# R7FA6M1AD register map
Vendor: Renesas; Series: RA6; File version: 1.2
CPU: CM4 r0p1, little endian, MPU, FPU, VTOR, 4 interrupt priority bits
Registers are 8-bit, read-write, reset 0x0 unless marked. A register's access mark holds for its fields unless they carry their own. Offsets are from the block's base; [hi:lo] are bit positions; {n}, {i} and the like mark numbered series.

## POEG — Port Output Enable Module for GPT
Base 0x40042000
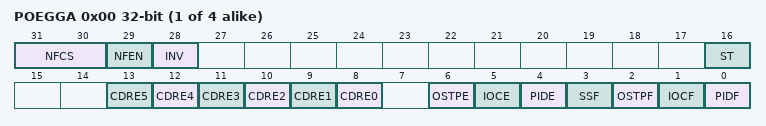
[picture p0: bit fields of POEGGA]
0x00 POEGG{x} (x=A,B,C,D; step 0x100) 32-bit — POEG Group {x} Setting Register
  [31:30] NFCS — Noise Filter Clock Select
  [29] NFEN — Noise Filter Enable
  [28] INV — GTETRG Input Reverse
  [16] ST ro — GTETRG Input Status Flag
  [n+8] CDRE{n} (n=0..5) — Comparator Disable Request Enable {n}Note: Can be modified only once after a reset.
  [6] OSTPE — Oscillation Stop Detection EnableNote: Can be modified only once after a reset.
  [5] IOCE — Enable for GPT Output,Disable RequestNote: Can be modified only once after a reset.
  [4] PIDE — Port Input Detection EnableNote: Can be modified only once after a reset.
  [3] SSF — Software Stop Flag
  [2] OSTPF write-0-clears read-modifies — Oscillation Stop Detection Flag
  [1] IOCF write-0-clears read-modifies — Real Time Overcurrent Detection Flag
  [0] PIDF write-0-clears read-modifies — Port Input Detection Flag

## GPT_ODC — PWM Delay Generation Circuit
Base 0x4007B000
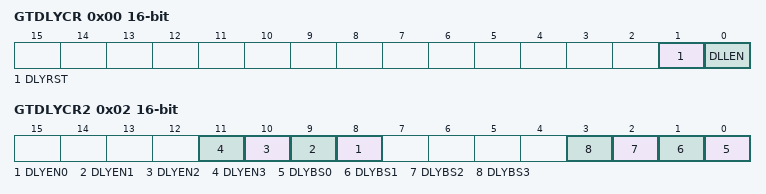
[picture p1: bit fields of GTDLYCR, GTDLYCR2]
0x00 GTDLYCR 16-bit — PWM Output Delay Control Register
  [1] DLYRST — PWM Delay Generation Circuit Reset
  [0] DLLEN — DLL Operation Enable
0x02 GTDLYCR2 16-bit — PWM Output Delay Control Register2
  [n+8] DLYEN{n} (n=0..3) — PWM Delay Generation Circuit enable for channel {n}
  [n] DLYBS{n} (n=0..3) — PWM Delay Generation Circuit bypass for channel {n}
{0x18+4i} GTDLYR{i}A (i=0..3) 16-bit (alternate view of GTDLYR{i}) — GTIOC{i}A Rising Output Delay Register
  [4:0] DLY — GTIOCnA Output Rising Edge Delay Setting
{0x1A+4i} GTDLYR{i}B (i=0..3) 16-bit (alternate view of GTDLYR{i}) — GTIOC{i}B Rising Output Delay Register
  [4:0] DLY — GTIOCnB Output Rising Edge Delay Setting
{0x28+4i} GTDLYF{i}A (i=0..3) 16-bit (alternate view of GTDLYF{i}) — GTIOC{i}A Falling Output Delay Register
  [4:0] DLY — GTIOCnA Output Falling Edge Delay Setting
{0x2A+4i} GTDLYF{i}B (i=0..3) 16-bit (alternate view of GTDLYF{i}) — GTIOC{i}B Falling Output Delay Register
  [4:0] DLY — GTIOCnB Output Falling Edge Delay Setting

## PORT0 — Port 0 Control Registers
Base 0x40040000
Same registers: PORT5 0x400400A0, PORT6 0x400400C0, PORT7 0x400400E0
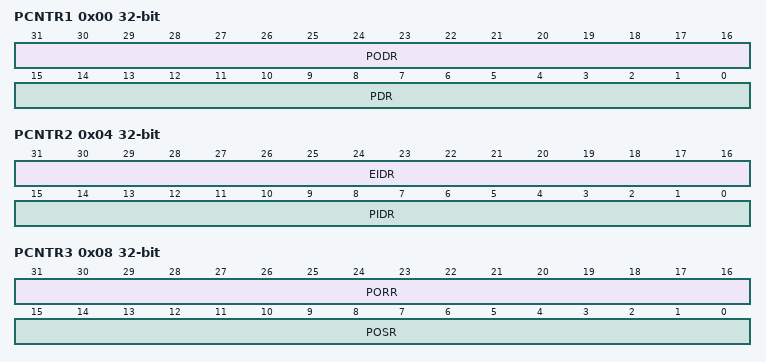
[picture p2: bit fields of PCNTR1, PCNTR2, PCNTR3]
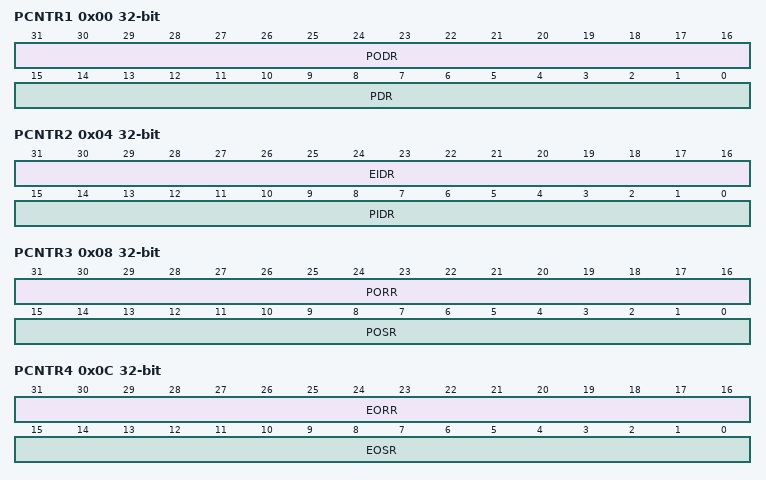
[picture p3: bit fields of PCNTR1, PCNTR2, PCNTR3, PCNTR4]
0x00 PCNTR1 32-bit — Port Control Register 1
  [31:16] PODR — Pmn Output Data
  [15:0] PDR — Pmn Direction
0x00 PODR 16-bit (alternate view of PCNTR1) — Output data register
  [15:0] PODR — Pmn Output Data
0x02 PDR 16-bit (alternate view of PCNTR1) — Data direction register
  [15:0] PDR — Pmn Direction
0x04 PCNTR2 32-bit ro (reset mask 0xFFFF0000) — Port Control Register 2
  [31:16] EIDR — Pmn Event Input Data
  [15:0] PIDR — Pmn Input Data
0x06 PIDR 16-bit ro reset not defined (alternate view of PCNTR2) — Input data register
  [15:0] PIDR — Pmn Input Data
0x08 PCNTR3 32-bit wo — Port Control Register 3
  [31:16] PORR — Pmn Output Reset
  [15:0] POSR — Pmn Output Set
0x08 PORR 16-bit wo (alternate view of PCNTR3) — Output reset register
  [15:0] PORR — Pmn Output Reset
0x0A POSR 16-bit wo (alternate view of PCNTR3) — Output set register
  [15:0] POSR — Pmn Output Set

## PORT1 — Port 1 Control Registers
Base 0x40040020
Same registers: PORT2 0x40040040, PORT3 0x40040060, PORT4 0x40040080
0x00 PCNTR1 32-bit — Port Control Register 1
  [31:16] PODR — Pmn Output Data
  [15:0] PDR — Pmn Direction
0x00 PODR 16-bit (alternate view of PCNTR1) — Output data register
  [15:0] PODR — Pmn Output Data
0x02 PDR 16-bit (alternate view of PCNTR1) — Data direction register
  [15:0] PDR — Pmn Direction
0x04 PCNTR2 32-bit ro (reset mask 0xFFFF0000) — Port Control Register 2
  [31:16] EIDR — Pmn Event Input Data
  [15:0] PIDR — Pmn Input Data
0x04 EIDR 16-bit ro reset not defined (alternate view of PCNTR2) — Event input data register
  [15:0] EIDR — Pmn Event Input Data
0x06 PIDR 16-bit ro reset not defined (alternate view of PCNTR2) — Input data register
  [15:0] PIDR — Pmn Input Data
0x08 PCNTR3 32-bit wo — Port Control Register 3
  [31:16] PORR — Pmn Output Reset
  [15:0] POSR — Pmn Output Set
0x08 PORR 16-bit wo (alternate view of PCNTR3) — Output set register
  [15:0] PORR — Pmn Output Reset
0x0A POSR 16-bit wo (alternate view of PCNTR3) — Output reset register
  [15:0] POSR — Pmn Output Set
0x0C PCNTR4 32-bit — Port Control Register 4
  [31:16] EORR — Pmn Event Output Reset
  [15:0] EOSR — Pmn Event Output Set
0x0C EORR 16-bit (alternate view of PCNTR4) — Event output set register
  [15:0] EORR — Pmn Event Output Reset
0x0E EOSR 16-bit (alternate view of PCNTR4) — Event output reset register
  [15:0] EOSR — Pmn Event Output Set
